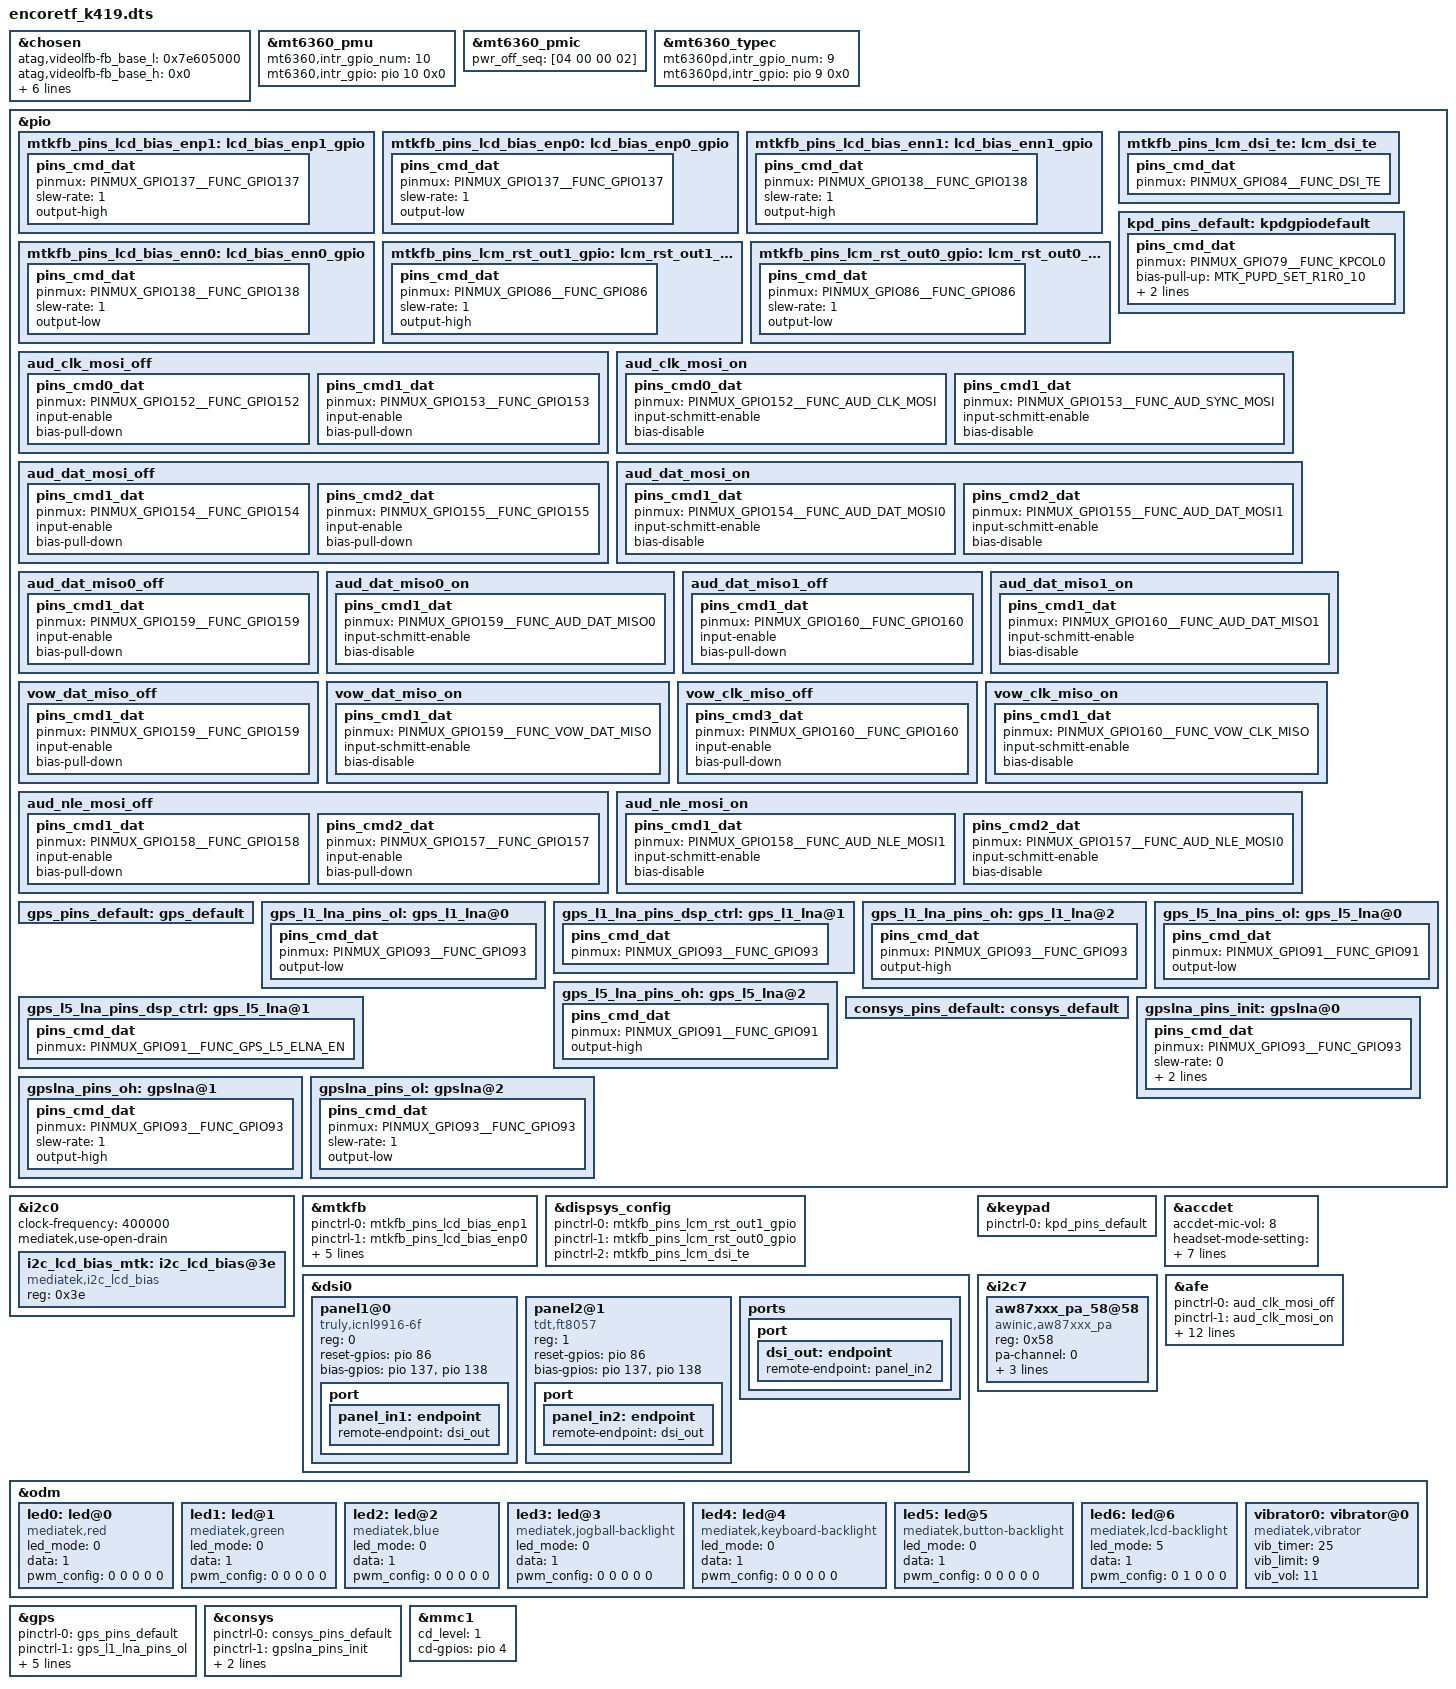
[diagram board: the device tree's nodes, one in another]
// SPDX-License-Identifier: GPL-2.0
/dts-v1/;
/plugin/;
#include <dt-bindings/interrupt-controller/irq.h>
#include <dt-bindings/interrupt-controller/arm-gic.h>
#ifndef CONFIG_FPGA_EARLY_PORTING
#include <dt-bindings/pinctrl/mt6833-pinfunc.h>
#endif

/* chosen */
&chosen {
	atag,videolfb-fb_base_l = <0x7e605000>;
	atag,videolfb-fb_base_h = <0x0>;
	atag,videolfb-islcmfound = <1>;
	atag,videolfb-islcm_inited = <0>;
	atag,videolfb-fps= <6000>;
	atag,videolfb-vramSize= <0x1be0000>;
	atag,videolfb-lcmname=
		"nt35595_fhd_dsi_cmd_truly_nt50358_drv";
};

&mt6360_pmu {
	mt6360,intr_gpio_num = <10>; /* direct defined GPIO num */
	mt6360,intr_gpio = <&pio 10 0x0>;
};

&mt6360_pmic {
	pwr_off_seq = [04 00 00 02];
};

&mt6360_typec {
/* Modify-start by baiwei.peng for type-c pd eint on 2022/03/15 */
	mt6360pd,intr_gpio_num = <9>; /* direct defined GPIO num */
	mt6360pd,intr_gpio = <&pio 9 0x0>;
/* Modify-end by baiwei.peng for type-c pd eint on 2022/03/15 */
};

#ifndef CONFIG_FPGA_EARLY_PORTING
&pio {
	mtkfb_pins_lcd_bias_enp1: lcd_bias_enp1_gpio {
		pins_cmd_dat {
			pinmux = <PINMUX_GPIO137__FUNC_GPIO137>;
			slew-rate = <1>;
			output-high;
		};
	};

	mtkfb_pins_lcd_bias_enp0: lcd_bias_enp0_gpio {
		pins_cmd_dat {
			pinmux = <PINMUX_GPIO137__FUNC_GPIO137>;
			slew-rate = <1>;
			output-low;
		};
	};

	mtkfb_pins_lcd_bias_enn1: lcd_bias_enn1_gpio {
		pins_cmd_dat {
			pinmux = <PINMUX_GPIO138__FUNC_GPIO138>;
			slew-rate = <1>;
			output-high;
		};
	};

	mtkfb_pins_lcd_bias_enn0: lcd_bias_enn0_gpio {
		pins_cmd_dat {
			pinmux = <PINMUX_GPIO138__FUNC_GPIO138>;
			slew-rate = <1>;
			output-low;
		};
	};

	mtkfb_pins_lcm_rst_out1_gpio: lcm_rst_out1_gpio {
		pins_cmd_dat {
			pinmux = <PINMUX_GPIO86__FUNC_GPIO86>;
			slew-rate = <1>;
			output-high;
		};
	};

	mtkfb_pins_lcm_rst_out0_gpio: lcm_rst_out0_gpio {
		pins_cmd_dat {
			pinmux = <PINMUX_GPIO86__FUNC_GPIO86>;
			slew-rate = <1>;
			output-low;
		};
	};
	mtkfb_pins_lcm_dsi_te: lcm_dsi_te {
		pins_cmd_dat {
			pinmux = <PINMUX_GPIO84__FUNC_DSI_TE>;
		};
	};
};


/* LCD Bias I2C */
&i2c0 {
	#address-cells = <1>;
	#size-cells = <0>;
	clock-frequency = <400000>;
	mediatek,use-open-drain;
	i2c_lcd_bias_mtk:i2c_lcd_bias@3e {
		compatible = "mediatek,i2c_lcd_bias";
		reg = <0x3e>;
		status = "okay";
	 };
};

/* for reset && +-5.5V pin control */
&mtkfb {
	pinctrl-names = "lcd_bias_enp1_gpio", "lcd_bias_enp0_gpio",
		"lcd_bias_enn1_gpio", "lcd_bias_enn0_gpio",
		"lcm_rst_out1_gpio", "lcm_rst_out0_gpio",
		"mode_te_te";
	pinctrl-0 = <&mtkfb_pins_lcd_bias_enp1>;
	pinctrl-1 = <&mtkfb_pins_lcd_bias_enp0>;
	pinctrl-2 = <&mtkfb_pins_lcd_bias_enn1>;
	pinctrl-3 = <&mtkfb_pins_lcd_bias_enn0>;
	pinctrl-4 = <&mtkfb_pins_lcm_rst_out1_gpio>;
	pinctrl-5 = <&mtkfb_pins_lcm_rst_out0_gpio>;
	pinctrl-6 = <&mtkfb_pins_lcm_dsi_te>;
	status = "okay";
};
&dispsys_config {
	pinctrl-names =
		"lcm_rst_out1_gpio", "lcm_rst_out0_gpio",
		"mode_te_te";
	pinctrl-0 = <&mtkfb_pins_lcm_rst_out1_gpio>;
	pinctrl-1 = <&mtkfb_pins_lcm_rst_out0_gpio>;
	pinctrl-2 = <&mtkfb_pins_lcm_dsi_te>;
	status = "okay";
};

&dsi0 {
	status = "okay";
	#address-cells = <1>;
	#size-cells = <0>;
	//fake_heigh = <1920>;
	//fake_width = <1080>;

	panel1@0 {
		compatible = "truly,icnl9916-6f";
		reg = <0>;
		//pm-enable-gpios = <&pio 136 0>; /* PERIEN_LCM_LED_EN */
		reset-gpios = <&pio 86 0>; /* LCM reset */
		bias-gpios = <&pio 137 0>, <&pio 138 0>; /* +-5.5V */
		pinctrl-names = "default";
		port {
			panel_in1: endpoint {
				remote-endpoint = <&dsi_out>;
			};
		};
	};

	 panel2@1 {
		compatible = "tdt,ft8057";
		reg = <1>;
//		pm-enable-gpios = <&pio 136 0>;
		reset-gpios = <&pio 86 0>;
		bias-gpios = <&pio 137 0>,
			<&pio 138 0>;
		pinctrl-names = "default";
		port {
			panel_in2: endpoint {
				remote-endpoint = <&dsi_out>;
			};
		};
	};
	ports {
		port {
			dsi_out: endpoint {
				remote-endpoint = <&panel_in2>;
			};
		};
	};
};
#endif

&keypad {
	pinctrl-names = "default";
	pinctrl-0 = <&kpd_pins_default>;
};

&pio {
	kpd_pins_default: kpdgpiodefault {
		pins_cmd_dat {
			pinmux = <PINMUX_GPIO79__FUNC_KPCOL0>;
			bias-pull-up = <MTK_PUPD_SET_R1R0_10>;
			output-low;
			input-schmitt-enable;
		};
	};
};



/* accdet start */
&accdet {
	/* accdet micbias voltage: 0x09:2.85v 0x08:2.8v 0x07,
	 * 2.7v;0x05,2.5v;0x02,1.9v
	 */
	accdet-mic-vol = <8>;
	/* accdet pwm_width, pwm_thresh, fall_delay, rise_delay
	 * debounce0, debounce1, debounce3, debounce4
	 * eint pwm_width, eint pwm_thresh
	 * eint deb(debounce0, debounce1, debounce2, debounce3), inv_debounce
	 */
	headset-mode-setting = <0x500 0x500 1 0x1f0
				0x800 0x800 0x20 0x44
				0x4 0x1
				0x5 0x3 0x3 0x5 0xe>;
	accdet-plugout-debounce = <1>;
	/*1:ACC mode, 2:low cost without in bias, 6:low cost with in bias*/
	accdet-mic-mode = <1>;
	/*0--MD_MAX--UP_MAX--DW_MAX*/
	headset-three-key-threshold = <0 80 220 400>;
	headset-three-key-threshold-CDD = <0 121 192 600>;
	/*0--MD_MAX--VOICE_MAX--UP_MAX--DW_MAX*/
	headset-four-key-threshold = <0 58 121 192 400>;

	/* select VTH to 2v and 500k, use internal resitance */
	eint_use_ext_res = <0>;
	status = "okay";
};
/* accdet end */
/*add begin by haimei.liu@tcl.com.task:11061043.2021/4/29.audio speaker pa aw87359 porting*/
&i2c7 {
       /* AWINIC AW87359 Smart K PA */
       aw87xxx_pa_58@58 {
               compatible = "awinic,aw87xxx_pa";
               reg = <0x58>;
               //reset-gpio = <&pio 63 0>;
               pa-channel = < 0 >;
               monitor-flag = <0>; //1=enable
               monitor-timer-val = <3000>; //time interval, ms
               monitor-timer-count-max = <5>; //counts for average
               status = "okay";
       };
       /* AWINIC AW87359 Smart K PA End */
};
/*add begin by haimei.liu@tcl.com.task:11061043.2021/4/29.audio speaker pa aw87359 porting*/
&afe {
    pinctrl-names = "aud_clk_mosi_off",
				"aud_clk_mosi_on",
				"aud_dat_mosi_off",
				"aud_dat_mosi_on",
				"aud_dat_miso0_off",
				"aud_dat_miso0_on",
				"aud_dat_miso1_off",
				"aud_dat_miso1_on",
				"vow_dat_miso_off",
				"vow_dat_miso_on",
				"vow_clk_miso_off",
				"vow_clk_miso_on",
				"aud_nle_mosi_off",
				"aud_nle_mosi_on";

		pinctrl-0 = <&aud_clk_mosi_off>;
		pinctrl-1 = <&aud_clk_mosi_on>;
		pinctrl-2 = <&aud_dat_mosi_off>;
		pinctrl-3 = <&aud_dat_mosi_on>;
		pinctrl-4 = <&aud_dat_miso0_off>;
		pinctrl-5 = <&aud_dat_miso0_on>;
		pinctrl-6 = <&aud_dat_miso1_off>;
		pinctrl-7 = <&aud_dat_miso1_on>;
		pinctrl-8 = <&vow_dat_miso_off>;
		pinctrl-9 = <&vow_dat_miso_on>;
		pinctrl-10 = <&vow_clk_miso_off>;
		pinctrl-11 = <&vow_clk_miso_on>;
		pinctrl-12 = <&aud_nle_mosi_off>;
		pinctrl-13 = <&aud_nle_mosi_on>;
};
&pio {
	aud_clk_mosi_off: aud_clk_mosi_off {
		pins_cmd0_dat {
			pinmux = <PINMUX_GPIO152__FUNC_GPIO152>;
			input-enable;
			bias-pull-down;
		};
		pins_cmd1_dat {
			pinmux = <PINMUX_GPIO153__FUNC_GPIO153>;
			input-enable;
			bias-pull-down;
		};
	};
	aud_clk_mosi_on: aud_clk_mosi_on {
		pins_cmd0_dat {
			pinmux = <PINMUX_GPIO152__FUNC_AUD_CLK_MOSI>;
			input-schmitt-enable;
			bias-disable;
		};
		pins_cmd1_dat {
			pinmux = <PINMUX_GPIO153__FUNC_AUD_SYNC_MOSI>;
			input-schmitt-enable;
			bias-disable;
		};
	};
	aud_dat_mosi_off: aud_dat_mosi_off {
		pins_cmd1_dat {
			pinmux = <PINMUX_GPIO154__FUNC_GPIO154>;
			input-enable;
			bias-pull-down;
		};
		pins_cmd2_dat {
			pinmux = <PINMUX_GPIO155__FUNC_GPIO155>;
			input-enable;
			bias-pull-down;
		};
	};
	aud_dat_mosi_on: aud_dat_mosi_on {
		pins_cmd1_dat {
			pinmux = <PINMUX_GPIO154__FUNC_AUD_DAT_MOSI0>;
			input-schmitt-enable;
			bias-disable;
		};
		pins_cmd2_dat {
			pinmux = <PINMUX_GPIO155__FUNC_AUD_DAT_MOSI1>;
			input-schmitt-enable;
			bias-disable;
		};
	};
	aud_dat_miso0_off: aud_dat_miso0_off {
		pins_cmd1_dat {
			pinmux = <PINMUX_GPIO159__FUNC_GPIO159>;
			input-enable;
			bias-pull-down;
		};
	};
	aud_dat_miso0_on: aud_dat_miso0_on {
		pins_cmd1_dat {
			pinmux = <PINMUX_GPIO159__FUNC_AUD_DAT_MISO0>;
			input-schmitt-enable;
			bias-disable;
		};
	};
	aud_dat_miso1_off: aud_dat_miso1_off {
		pins_cmd1_dat {
			pinmux = <PINMUX_GPIO160__FUNC_GPIO160>;
			input-enable;
			bias-pull-down;
		};
	};
	aud_dat_miso1_on: aud_dat_miso1_on {
		pins_cmd1_dat {
			pinmux = <PINMUX_GPIO160__FUNC_AUD_DAT_MISO1>;
			input-schmitt-enable;
			bias-disable;
		};
	};

	vow_dat_miso_off: vow_dat_miso_off {
		pins_cmd1_dat {
			pinmux = <PINMUX_GPIO159__FUNC_GPIO159>;
			input-enable;
			bias-pull-down;
		};
	};
	vow_dat_miso_on: vow_dat_miso_on {
		pins_cmd1_dat {
			pinmux = <PINMUX_GPIO159__FUNC_VOW_DAT_MISO>;
			input-schmitt-enable;
			bias-disable;
		};
	};
	vow_clk_miso_off: vow_clk_miso_off {
		pins_cmd3_dat {
			pinmux = <PINMUX_GPIO160__FUNC_GPIO160>;
			input-enable;
			bias-pull-down;
		};
	};
	vow_clk_miso_on: vow_clk_miso_on {
		pins_cmd1_dat {
			pinmux = <PINMUX_GPIO160__FUNC_VOW_CLK_MISO>;
			input-schmitt-enable;
			bias-disable;
		};
	};
	aud_nle_mosi_off: aud_nle_mosi_off {
		pins_cmd1_dat {
			pinmux = <PINMUX_GPIO158__FUNC_GPIO158>;
			input-enable;
			bias-pull-down;
		};
		pins_cmd2_dat {
			pinmux = <PINMUX_GPIO157__FUNC_GPIO157>;
			input-enable;
			bias-pull-down;
		};
	};
	aud_nle_mosi_on: aud_nle_mosi_on {
		pins_cmd1_dat {
			pinmux = <PINMUX_GPIO158__FUNC_AUD_NLE_MOSI1>;
			input-schmitt-enable;
			bias-disable;
		};
		pins_cmd2_dat {
			pinmux = <PINMUX_GPIO157__FUNC_AUD_NLE_MOSI0>;
			input-schmitt-enable;
			bias-disable;
		};
	};
};
//End added by lanying.he for XR11082897 on 2021/05/06

&odm {
	led0:led@0 {
		compatible = "mediatek,red";
		led_mode = <0>;
		data = <1>;
		pwm_config = <0 0 0 0 0>;
	};
	led1:led@1 {
		compatible = "mediatek,green";
		led_mode = <0>;
		data = <1>;
		pwm_config = <0 0 0 0 0>;
	};
	led2:led@2 {
		compatible = "mediatek,blue";
		led_mode = <0>;
		data = <1>;
		pwm_config = <0 0 0 0 0>;
	};
	led3:led@3 {
		compatible = "mediatek,jogball-backlight";
		led_mode = <0>;
		data = <1>;
		pwm_config = <0 0 0 0 0>;
	};
	led4:led@4 {
		compatible = "mediatek,keyboard-backlight";
		led_mode = <0>;
		data = <1>;
		pwm_config = <0 0 0 0 0>;
	};
	led5:led@5 {
		compatible = "mediatek,button-backlight";
		led_mode = <0>;
		data = <1>;
		pwm_config = <0 0 0 0 0>;
	};
	led6:led@6 {
		compatible = "mediatek,lcd-backlight";
		led_mode = <5>;
		data = <1>;
		pwm_config = <0 1 0 0 0>;
	};
	vibrator0:vibrator@0 {
		compatible = "mediatek,vibrator";
		vib_timer = <25>;
		vib_limit = <9>;
		vib_vol= <11>; //Modified by baiwei.peng for vibrator effect
	};
};
/* GPS GPIO standardization start */
&pio {
	gps_pins_default: gps_default {
	};

	gps_l1_lna_pins_ol: gps_l1_lna@0 {
		pins_cmd_dat {
			pinmux = <PINMUX_GPIO93__FUNC_GPIO93>;
			output-low;
		};
	};
	gps_l1_lna_pins_dsp_ctrl: gps_l1_lna@1 {
		pins_cmd_dat {
			pinmux = <PINMUX_GPIO93__FUNC_GPIO93>;
		};
	};
	gps_l1_lna_pins_oh: gps_l1_lna@2 {
		pins_cmd_dat {
			pinmux = <PINMUX_GPIO93__FUNC_GPIO93>;
			output-high;
		};
	};

	gps_l5_lna_pins_ol: gps_l5_lna@0 {
		pins_cmd_dat {
			pinmux = <PINMUX_GPIO91__FUNC_GPIO91>;
			output-low;
		};
	};
	gps_l5_lna_pins_dsp_ctrl: gps_l5_lna@1 {
		pins_cmd_dat {
			pinmux = <PINMUX_GPIO91__FUNC_GPS_L5_ELNA_EN>;
		};
	};
	gps_l5_lna_pins_oh: gps_l5_lna@2 {
		pins_cmd_dat {
			pinmux = <PINMUX_GPIO91__FUNC_GPIO91>;
			output-high;
		};
	};
};

&gps {
	pinctrl-names = "default",
		"gps_l1_lna_disable",
		"gps_l1_lna_dsp_ctrl",
		"gps_l1_lna_enable",
		"gps_l5_lna_disable",
		"gps_l5_lna_dsp_ctrl",
		"gps_l5_lna_enable";
	pinctrl-0 = <&gps_pins_default>;
	pinctrl-1 = <&gps_l1_lna_pins_ol>;
	pinctrl-2 = <&gps_l1_lna_pins_dsp_ctrl>;
	pinctrl-3 = <&gps_l1_lna_pins_oh>;
	pinctrl-4 = <&gps_l5_lna_pins_ol>;
	pinctrl-5 = <&gps_l5_lna_pins_dsp_ctrl>;
	pinctrl-6 = <&gps_l5_lna_pins_oh>;
	status = "okay";
};
/* GPS GPIO standardization end */
//BEGIN add by wang.zhou for gps lna pin ENCORETF-35
&pio {
        consys_pins_default: consys_default {
        };
        gpslna_pins_init: gpslna@0 {
                pins_cmd_dat {
                        pinmux = <PINMUX_GPIO93__FUNC_GPIO93>;
                        slew-rate = <0>;
                        bias-disable;
                        output-low;
                };
        };
        gpslna_pins_oh: gpslna@1 {
                pins_cmd_dat {
                        pinmux = <PINMUX_GPIO93__FUNC_GPIO93>;
                        slew-rate = <1>;
                        output-high;
                };
        };
        gpslna_pins_ol: gpslna@2 {
                pins_cmd_dat {
                        pinmux = <PINMUX_GPIO93__FUNC_GPIO93>;
                        slew-rate = <1>;
                        output-low;
                };
        };
};
&consys {
        pinctrl-names = "default", "gps_lna_state_init",
                "gps_lna_state_oh", "gps_lna_state_ol";
        pinctrl-0 = <&consys_pins_default>;
        pinctrl-1 = <&gpslna_pins_init>;
        pinctrl-2 = <&gpslna_pins_oh>;
        pinctrl-3 = <&gpslna_pins_ol>;
        status = "okay";
};
//END add by wang.zhou for gps lna pin ENCORETF-35

/*Add-start by baiwei.peng for sdcard porting on 2022/03/02 */
&mmc1 {
	cd_level = /bits/ 8 <1>;
	cd-gpios = <&pio 4 0>;
};
/*Add-end by baiwei.peng for sdcard porting on 2022/03/02 */

/*Begin ersen.shang for SOCAOSP13-6985 EncoreTF Camera BringUp 2022-06*/
#include "mediatek/cust_mt6833_encoretf_camera.dtsi"
/*End   ersen.shang for SOCAOSP13-6985 EncoreTF Camera BringUp 2022-06*/

#include <encoretf_k419/cust.dtsi>
#include "mediatek/cust_mt6833_touch_encore_k419.dtsi"     
#include "mediatek/bat_setting/encore/encore_charge.dtsi"
#include "mediatek/bat_setting/encore/encore_battery_prop.dtsi"


//start, qiaozhen.li, 2022/3/18, fingerprint porting
#include "mediatek/encoretf_k419_fpsensor.dtsi"
//#include "mediatek/buffalotmo-sunwave_fp.dtsi"
//end, qiaozhen.li, 2022/3/18, fingerprint porting

/*End of this file, DO NOT ADD ANYTHING HERE*/
